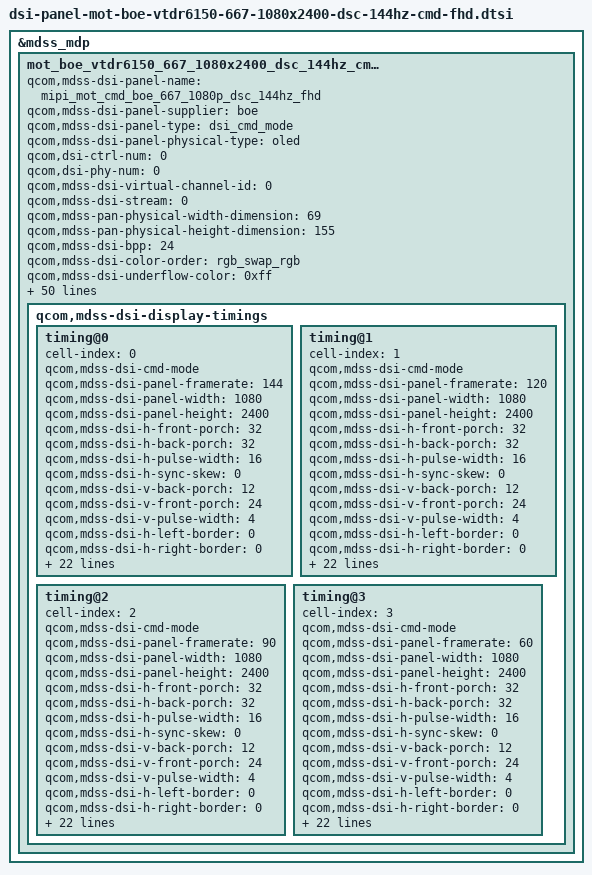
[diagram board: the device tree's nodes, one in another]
/* Copyright (c) 2019-2021, The Linux Foundation. All rights reserved.
 *
 * This program is free software; you can redistribute it and/or modify
 * it under the terms of the GNU General Public License version 2 and
 * only version 2 as published by the Free Software Foundation.
 *
 * This program is distributed in the hope that it will be useful,
 * but WITHOUT ANY WARRANTY; without even the implied warranty of
 * MERCHANTABILITY or FITNESS FOR A PARTICULAR PURPOSE.  See the
 * GNU General Public License for more details.
 */
&mdss_mdp {
	mot_boe_vtdr6150_667_1080x2400_dsc_144hz_cmd_fhd: qcom,mdss_dsi_mot_boe_vtdr6150_667_1080x2400_144hz_cmd_fhd {
		qcom,mdss-dsi-panel-name = "mipi_mot_cmd_boe_667_1080p_dsc_144hz_fhd";
		qcom,mdss-dsi-panel-supplier = "boe";
		qcom,mdss-dsi-panel-type = "dsi_cmd_mode";
		qcom,mdss-dsi-panel-physical-type = "oled";
		qcom,dsi-ctrl-num = <0>;
		qcom,dsi-phy-num = <0>;
		qcom,mdss-dsi-virtual-channel-id = <0>;
		qcom,mdss-dsi-stream = <0>;
		qcom,mdss-pan-physical-width-dimension = <69>;
		qcom,mdss-pan-physical-height-dimension = <155>;
		qcom,mdss-dsi-bpp = <24>;
		qcom,mdss-dsi-color-order = "rgb_swap_rgb";
		qcom,mdss-dsi-underflow-color = <0xff>;
		qcom,mdss-dsi-border-color = <0>;

		qcom,mdss-dsi-traffic-mode = "non_burst_sync_event";
		qcom,mdss-dsi-bllp-eof-power-mode;
		qcom,mdss-dsi-bllp-power-mode;
		qcom,mdss-dsi-lane-0-state;
		qcom,mdss-dsi-lane-1-state;
		qcom,mdss-dsi-lane-2-state;
		qcom,mdss-dsi-lane-3-state;
		qcom,mdss-dsi-dma-trigger = "trigger_sw";
		qcom,mdss-dsi-mdp-trigger = "none";
		qcom,mdss-dsi-reset-sequence = <0 0>, <1 2>, <0 2>, <1 20>;

		qcom,mdss-dsi-tx-eot-append;
		qcom,mdss-dsi-te-pin-select = <1>;
		qcom,mdss-dsi-te-dcs-command = <1>;
		qcom,mdss-dsi-te-check-enable;
		qcom,mdss-dsi-te-using-te-pin;

		qcom,mdss-dsi-dc-off-command = [
				39 01 00 00 00 00 02 5E 00];
		qcom,mdss-dsi-dc-off-command-state = "dsi_hs_mode";
		qcom,mdss-dsi-dc-on-command = [
				39 01 00 00 00 00 02 5E 01];
		qcom,mdss-dsi-dc-on-command-state = "dsi_hs_mode";

		qcom,mdss-dsi-hbm-on-command = [
				39 00 00 40 00 00 03 51 0F FF
				39 01 00 00 00 00 02 62 00];
		qcom,mdss-dsi-hbm-off-command = [
				39 00 00 40 00 00 02 62 00
				39 01 00 00 00 00 03 51 05 2A];

		qcom,mdss-dsi-hbm-fod;
		qcom,mdss-dsi-hbm-fod-on-command = [
				39 00 00 40 00 00 05 63 10 00 05 29
				39 01 00 00 00 00 02 62 03];

		qcom,mdss-dsi-panel-lhbm-wait-fps-valid;
		qcom,mdss-dsi-panel-local-hbm-wait-fps-count = <30>;
		qcom,mdss-dsi-panel-local-hbm-wait-fps-interval = <1>;
		qcom,mdss-dsi-panel-lhbm-not-allowed-fps-list = <60 90>;

		qcom,mdss-dsi-panel-local-hbm-enabled;
              	qcom,mdss-dsi-panel-local-hbm-DDIC-type = <0x6150>;
		qcom,mdss-dsi-panel-local-hbm-DC-HYBIRD-THRESHOLD-BL = <1321>; //0x0529
		qcom,mdss-dsi-panel-local-hbm-alpha-register = <0x63>;
		qcom,mdss-dsi-panel-local-hbm-alpha-size = <4096>;
		qcom,mdss-dsi-panel-bl-num = <1>;
		qcom,mdss-dsi-panel-local-hbm-alpha-table = <
				0 872 891 893 893 893 893 894 895 895 894 894 894 894 909 908
				909 910 910 911 910 909 910 910 912 913 911 929 929 929 930 931
				931 931 931 932 932 932 932 932 945 945 946 946 948 948 948 948
				949 949 948 948 966 966 965 965 966 965 964 967 967 967 967 968
				967 983 983 984 983 983 984 984 985 987 986 986 986 986 1001 1000
				1000 1001 1001 1001 1002 1002 1002 1004 1002 1003 1018 1019 1019 1018 1019 1019
				1019 1019 1019 1020 1020 1020 1023 1035 1036 1035 1035 1035 1035 1035 1035 1035
				1035 1037 1036 1036 1052 1053 1052 1052 1052 1051 1052 1053 1052 1053 1053 1054
				1053 1067 1070 1070 1071 1071 1071 1071 1070 1071 1071 1070 1071 1084 1083 1083
				1086 1086 1086 1087 1086 1087 1086 1087 1088 1088 1101 1102 1102 1102 1103 1105
				1105 1105 1105 1105 1104 1104 1105 1117 1118 1117 1117 1118 1118 1120 1120 1120
				1120 1119 1118 1134 1134 1134 1133 1134 1134 1135 1134 1137 1136 1136 1137 1136
				1150 1151 1151 1152 1150 1151 1151 1151 1152 1151 1153 1153 1153 1166 1166 1167
				1168 1167 1167 1168 1167 1168 1168 1168 1170 1183 1184 1183 1184 1185 1185 1183
				1184 1184 1185 1186 1185 1185 1201 1198 1199 1198 1199 1198 1199 1199 1199 1199
				1199 1199 1199 1213 1215 1215 1215 1215 1214 1215 1215 1215 1217 1217 1216 1217
				1229 1229 1229 1232 1233 1233 1234 1234 1233 1232 1233 1233 1245 1245 1245 1244
				1244 1246 1247 1247 1247 1248 1247 1247 1248 1260 1260 1260 1260 1261 1261 1263
				1262 1263 1264 1265 1264 1264 1276 1275 1274 1276 1276 1276 1276 1276 1280 1280
				1280 1280 1291 1291 1292 1292 1292 1293 1293 1293 1293 1294 1296 1295 1296 1308
				1308 1308 1308 1309 1309 1309 1307 1309 1308 1308 1311 1311 1322 1324 1324 1324
				1323 1323 1322 1325 1325 1324 1324 1324 1326 1339 1339 1339 1339 1349 1350 1350
				1350 1362 1361 1363 1361 1373 1373 1373 1373 1385 1385 1385 1384 1396 1396 1397
				1396 1407 1407 1407 1408 1418 1418 1417 1418 1430 1430 1431 1431 1443 1442 1444
				1445 1444 1454 1456 1456 1455 1465 1464 1466 1467 1477 1477 1476 1476 1486 1487
				1486 1486 1496 1496 1497 1498 1508 1509 1509 1511 1521 1520 1520 1520 1530 1529
				1530 1531 1540 1540 1541 1540 1542 1553 1553 1553 1552 1562 1561 1563 1564 1573
				1573 1573 1573 1583 1583 1583 1584 1593 1595 1594 1594 1604 1604 1604 1605 1612
				1613 1612 1613 1622 1624 1623 1626 1635 1635 1634 1633 1644 1646 1646 1647 1648
				1658 1657 1656 1657 1667 1667 1666 1666 1674 1676 1676 1677 1684 1686 1685 1685
				1694 1694 1694 1694 1704 1703 1704 1705 1714 1713 1712 1713 1721 1723 1723 1724
				1732 1733 1733 1736 1735 1745 1745 1745 1745 1754 1754 1754 1755 1763 1764 1764
				1762 1773 1773 1773 1773 1781 1780 1782 1780 1791 1790 1790 1788 1797 1798 1799
				1799 1808 1807 1808 1808 1816 1816 1816 1816 1819 1827 1828 1836 1836 1836 1843
				1843 1852 1853 1853 1861 1860 1869 1869 1869 1878 1879 1878 1887 1888 1896 1894
				1894 1904 1905 1912 1912 1911 1920 1920 1919 1928 1928 1936 1937 1936 1945 1944
				1950 1951 1952 1960 1958 1959 1967 1968 1975 1979 1979 1985 1985 1993 1993 1994
				2001 2002 2001 2009 2010 2018 2019 2019 2025 2027 2036 2034 2033 2042 2042 2041
				2049 2050 2058 2057 2058 2065 2063 2071 2070 2071 2078 2077 2078 2087 2087 2095
				2095 2094 2101 2101 2109 2109 2109 2114 2113 2118 2124 2126 2134 2132 2131 2139
				2139 2146 2146 2147 2154 2154 2153 2160 2162 2168 2168 2167 2175 2176 2182 2182
				2183 2191 2190 2190 2196 2199 2205 2204 2204 2211 2210 2217 2216 2217 2225 2223
				2223 2231 2231 2239 2238 2236 2243 2245 2251 2256 2255 2260 2262 2261 2268 2267
				2274 2274 2275 2281 2280 2288 2287 2288 2294 2294 2295 2301 2302 2308 2308 2309
				2313 2315 2321 2321 2322 2328 2329 2327 2334 2334 2340 2342 2341 2348 2348 2352
				2354 2355 2360 2360 2360 2368 2367 2373 2373 2377 2383 2382 2389 2389 2390 2397
				2396 2397 2402 2402 2407 2410 2408 2416 2416 2423 2422 2422 2428 2430 2429 2436
				2433 2440 2441 2441 2447 2446 2454 2453 2453 2459 2458 2458 2465 2467 2472 2472
				2473 2477 2478 2485 2485 2485 2491 2490 2495 2502 2506 2507 2512 2511 2519 2520
				2526 2534 2533 2539 2537 2544 2545 2550 2556 2553 2559 2560 2565 2566 2571 2572
				2576 2582 2580 2586 2585 2591 2592 2596 2604 2604 2609 2609 2614 2617 2621 2619
				2624 2632 2632 2637 2637 2642 2644 2649 2654 2655 2661 2662 2669 2667 2672 2674
				2679 2683 2682 2688 2689 2694 2695 2700 2705 2706 2710 2713 2716 2716 2720 2720
				2725 2732 2733 2735 2736 2741 2741 2747 2753 2754 2760 2764 2767 2767 2771 2771
				2776 2781 2781 2788 2787 2794 2793 2800 2805 2805 2810 2810 2816 2816 2821 2820
				2824 2827 2830 2834 2833 2839 2840 2845 2849 2850 2855 2854 2857 2857 2863 2863
				2869 2873 2873 2879 2880 2886 2884 2889 2893 2895 2900 2899 2902 2902 2909 2908
				2914 2917 2918 2923 2924 2928 2930 2935 2940 2940 2946 2946 2951 2949 2953 2955
				2959 2965 2963 2967 2969 2974 2974 2977 2981 2982 2987 2987 2992 2994 3001 3001
				3006 3011 3009 3014 3015 3018 3018 3025 3028 3028 3034 3035 3039 3039 3043 3044
				3050 3054 3055 3060 3058 3064 3063 3068 3071 3073 3076 3076 3081 3081 3087 3088
				3094 3097 3098 3103 3100 3107 3108 3113 3115 3115 3120 3120 3127 3126 3130 3128
				3135 3137 3139 3144 3142 3147 3148 3154 3156 3155 3160 3159 3165 3165 3167 3167
				3173 3178 3180 3180 3180 3184 3184 3188 3195 3195 3199 3199 3204 3203 3205 3216
				3218 3223 3229 3228 3231 3236 3238 3241 3245 3251 3251 3253 3257 3257 3259 3264
				3267 3268 3273 3278 3278 3284 3291 3292 3292 3296 3302 3301 3307 3308 3313 3313
				3319 3323 3324 3327 3332 3332 3336 3340 3342 3343 3346 3351 3354 3355 3359 3366
				3364 3369 3373 3373 3376 3382 3384 3385 3390 3394 3393 3397 3400 3403 3402 3407
				3409 3410 3413 3418 3420 3422 3429 3433 3433 3436 3442 3442 3447 3451 3452 3454
				3456 3462 3460 3466 3468 3468 3473 3477 3482 3481 3484 3489 3494 3495 3499 3504
				3503 3507 3511 3512 3515 3520 3523 3521 3527 3531 3533 3538 3540 3542 3542 3545
				3549 3550 3552 3557 3560 3559 3564 3568 3567 3572 3576 3580 3580 3586 3590 3589
				3594 3598 3594 3598 3600 3603 3608 3612 3612 3617 3621 3624 3626 3631 3632 3635
				3635 3639 3644 3649 3649 3654 3657 3660 3662 3664 3665 3669 3673 3679 3680 3680
				3683 3688 3692 3695 3699 3702 3707 3708 3712 3714 3719 3719 3720 3725 3731 3735
				3739 3738 3739 3743 3745 3750 3749 3751 3756 3762 3766 3769 3769 3770 3775 3777
				3783 3785 3783 3788 3791 3795 3801 3803 3803 3807 3811 3814 3820 3820 3822 3828
				3831 3835 3837 3838 3840 3842 3849 3853 3858 3856 3860 3862 3866 3870 3872 3872
				3876 3878 3882 3886 3885 3890 3893 3896 3901 3903 3902 3905 3908 3913 3917 3918
				3920 3922 3927 3930 3933 3936 3936 3938 3942 3945 3951 3951 3952 3958 3960 3964
				3968 3970 3970 3973 3978 3982 3984 3984 3990 3993 3995 3995 3999 4000 4003 4010
				4013 4015 4013 4018 4022 4024 4026 4031 4030 4033 4037 4042 4044 4046 4046 4048
				4053 4055 4060 4063 4063 4064 4065 4071 4076 4081 4096 4096 4096 4096 4096 4096
				4096 4096 4096 4096 4096 4096 4096 4096 4096 4096 4096 4096 4096 4096 4096 4096
				4096 4096 4096 4096 4096 4096 4096 4096 4096 4096 4096 4096 4096 4096 4096 4096
				4096 4096 4096 4096 4096 4096 4096 4096 4096 4096 4096 4096 4096 4096 4096 4096
				4096 4096 4096 4096 4096 4096 4096 4096 4096 4096 4096 4096 4096 4096 4096 4096
				4096 4096 4096 4096 4096 4096 4096 4096 4096 4096 4096 4096 4096 4096 4096 4096
				4096 4096 4096 4096 4096 4096 4096 4096 4096 4096 4096 4096 4096 4096 4096 4096
				4096 4096 4096 4096 4096 4096 4096 4096 4096 4096 4096 4096 4096 4096 4096 4096
				4096 4096 4096 4096 4096 4096 4096 4096 4096 4096 4096 4096 4096 4096 4096 4096
				4096 4096 4096 4096 4096 4096 4096 4096 4096 4096 4096 4096 4096 4096 4096 4096
				4096 4096 4096 4096 4096 4096 4096 4096 4096 4096 4096 4096 4096 4096 4096 4096
				4096 4096 4096 4096 4096 4096 4096 4096 4096 4096 4096 4096 4096 4096 4096 4096
				4096 4096 4096 4096 4096 4096 4096 4096 4096 4096 4096 4096 4096 4096 4096 4096
				4096 4096 4096 4096 4096 4096 4096 4096 4096 4096 4096 4096 4096 4096 4096 4096
				4096 4096 4096 4096 4096 4096 4096 4096 4096 4096 4096 4096 4096 4096 4096 4096
				4096 4096 4096 4096 4096 4096 4096 4096 4096 4096 4096 4096 4096 4096 4096 4096
				4096 4096 4096 4096 4096 4096 4096 4096 4096 4096 4096 4096 4096 4096 4096 4096
				4096 4096 4096 4096 4096 4096 4096 4096 4096 4096 4096 4096 4096 4096 4096 4096
				4096 4096 4096 4096 4096 4096 4096 4096 4096 4096 4096 4096 4096 4096 4096 4096
				4096 4096 4096 4096 4096 4096 4096 4096 4096 4096 4096 4096 4096 4096 4096 4096
				4096 4096 4096 4096 4096 4096 4096 4096 4096 4096 4096 4096 4096 4096 4096 4096
				4096 4096 4096 4096 4096 4096 4096 4096 4096 4096 4096 4096 4096 4096 4096 4096
				4096 4096 4096 4096 4096 4096 4096 4096 4096 4096 4096 4096 4096 4096 4096 4096
				4096 4096 4096 4096 4096 4096 4096 4096 4096 4096 4096 4096 4096 4096 4096 4096
				4096 4096 4096 4096 4096 4096 4096 4096 4096 4096 4096 4096 4096 4096 4096 4096
				4096 4096 4096 4096 4096 4096 4096 4096 4096 4096 4096 4096 4096 4096 4096 4096
				4096 4096 4096 4096 4096 4096 4096 4096 4096 4096 4096 4096 4096 4096 4096 4096
				4096 4096 4096 4096 4096 4096 4096 4096 4096 4096 4096 4096 4096 4096 4096 4096
				4096 4096 4096 4096 4096 4096 4096 4096 4096 4096 4096 4096 4096 4096 4096 4096
				4096 4096 4096 4096 4096 4096 4096 4096 4096 4096 4096 4096 4096 4096 4096 4096
				4096 4096 4096 4096 4096 4096 4096 4096 4096 4096 4096 4096 4096 4096 4096 4096
				4096 4096 4096 4096 4096 4096 4096 4096 4096 4096 4096 4096 4096 4096 4096 4096
				4096 4096 4096 4096 4096 4096 4096 4096 4096 4096 4096 4096 4096 4096 4096 4096
				4096 4096 4096 4096 4096 4096 4096 4096 4096 4096 4096 4096 4096 4096 4096 4096
				4096 4096 4096 4096 4096 4096 4096 4096 4096 4096 4096 4096 4096 4096 4096 4096
				4096 4096 4096 4096 4096 4096 4096 4096 4096 4096 4096 4096 4096 4096 4096 4096
				4096 4096 4096 4096 4096 4096 4096 4096 4096 4096 4096 4096 4096 4096 4096 4096
				4096 4096 4096 4096 4096 4096 4096 4096 4096 4096 4096 4096 4096 4096 4096 4096
				4096 4096 4096 4096 4096 4096 4096 4096 4096 4096 4096 4096 4096 4096 4096 4096
				4096 4096 4096 4096 4096 4096 4096 4096 4096 4096 4096 4096 4096 4096 4096 4096
				4096 4096 4096 4096 4096 4096 4096 4096 4096 4096 4096 4096 4096 4096 4096 4096
				4096 4096 4096 4096 4096 4096 4096 4096 4096 4096 4096 4096 4096 4096 4096 4096
				4096 4096 4096 4096 4096 4096 4096 4096 4096 4096 4096 4096 4096 4096 4096 4096
				4096 4096 4096 4096 4096 4096 4096 4096 4096 4096 4096 4096 4096 4096 4096 4096
				4096 4096 4096 4096 4096 4096 4096 4096 4096 4096 4096 4096 4096 4096 4096 4096
				4096 4096 4096 4096 4096 4096 4096 4096 4096 4096 4096 4096 4096 4096 4096 4096
				4096 4096 4096 4096 4096 4096 4096 4096 4096 4096 4096 4096 4096 4096 4096 4096
				4096 4096 4096 4096 4096 4096 4096 4096 4096 4096 4096 4096 4096 4096 4096 4096
				4096 4096 4096 4096 4096 4096 4096 4096 4096 4096 4096 4096 4096 4096 4096 4096
				4096 4096 4096 4096 4096 4096 4096 4096 4096 4096 4096 4096 4096 4096 4096 4096
				4096 4096 4096 4096 4096 4096 4096 4096 4096 4096 4096 4096 4096 4096 4096 4096
				4096 4096 4096 4096 4096 4096 4096 4096 4096 4096 4096 4096 4096 4096 4096 4096
				4096 4096 4096 4096 4096 4096 4096 4096 4096 4096 4096 4096 4096 4096 4096 4096
				4096 4096 4096 4096 4096 4096 4096 4096 4096 4096 4096 4096 4096 4096 4096 4096
				4096 4096 4096 4096 4096 4096 4096 4096 4096 4096 4096 4096 4096 4096 4096 4096
				4096 4096 4096 4096 4096 4096 4096 4096 4096 4096 4096 4096 4096 4096 4096 4096
				4096 4096 4096 4096 4096 4096 4096 4096 4096 4096 4096 4096 4096 4096 4096 4096
				4096 4096 4096 4096 4096 4096 4096 4096 4096 4096 4096 4096 4096 4096 4096 4096
				4096 4096 4096 4096 4096 4096 4096 4096 4096 4096 4096 4096 4096 4096 4096 4096
				4096 4096 4096 4096 4096 4096 4096 4096 4096 4096 4096 4096 4096 4096 4096 4096
				4096 4096 4096 4096 4096 4096 4096 4096 4096 4096 4096 4096 4096 4096 4096 4096
				4096 4096 4096 4096 4096 4096 4096 4096 4096 4096 4096 4096 4096 4096 4096 4096
				4096 4096 4096 4096 4096 4096 4096 4096 4096 4096 4096 4096 4096 4096 4096 4096
				4096 4096 4096 4096 4096 4096 4096 4096 4096 4096 4096 4096 4096 4096 4096 4096
				4096 4096 4096 4096 4096 4096 4096 4096 4096 4096 4096 4096 4096 4096 4096 4096
				4096 4096 4096 4096 4096 4096 4096 4096 4096 4096 4096 4096 4096 4096 4096 4096
				4096 4096 4096 4096 4096 4096 4096 4096 4096 4096 4096 4096 4096 4096 4096 4096
				4096 4096 4096 4096 4096 4096 4096 4096 4096 4096 4096 4096 4096 4096 4096 4096
				4096 4096 4096 4096 4096 4096 4096 4096 4096 4096 4096 4096 4096 4096 4096 4096
				4096 4096 4096 4096 4096 4096 4096 4096 4096 4096 4096 4096 4096 4096 4096 4096
				4096 4096 4096 4096 4096 4096 4096 4096 4096 4096 4096 4096 4096 4096 4096 4096
				4096 4096 4096 4096 4096 4096 4096 4096 4096 4096 4096 4096 4096 4096 4096 4096
				4096 4096 4096 4096 4096 4096 4096 4096 4096 4096 4096 4096 4096 4096 4096 4096
				4096 4096 4096 4096 4096 4096 4096 4096 4096 4096 4096 4096 4096 4096 4096 4096
				4096 4096 4096 4096 4096 4096 4096 4096 4096 4096 4096 4096 4096 4096 4096 4096
				4096 4096 4096 4096 4096 4096 4096 4096 4096 4096 4096 4096 4096 4096 4096 4096
				4096 4096 4096 4096 4096 4096 4096 4096 4096 4096 4096 4096 4096 4096 4096 4096
				4096 4096 4096 4096 4096 4096 4096 4096 4096 4096 4096 4096 4096 4096 4096 4096
				4096 4096 4096 4096 4096 4096 4096 4096 4096 4096 4096 4096 4096 4096 4096 4096
				4096 4096 4096 4096 4096 4096 4096 4096 4096 4096 4096 4096 4096 4096 4096 4096
				4096 4096 4096 4096 4096 4096 4096 4096 4096 4096 4096 4096 4096 4096 4096 4096
				4096 4096 4096 4096 4096 4096 4096 4096 4096 4096 4096 4096 4096 4096 4096 4096
				4096 4096 4096 4096 4096 4096 4096 4096 4096 4096 4096 4096 4096 4096 4096 4096
				4096 4096 4096 4096 4096 4096 4096 4096 4096 4096 4096 4096 4096 4096 4096 4096
				4096 4096 4096 4096 4096 4096 4096 4096 4096 4096 4096 4096 4096 4096 4096 4096
				4096 4096 4096 4096 4096 4096 4096 4096 4096 4096 4096 4096 4096 4096 4096 4096
				4096 4096 4096 4096 4096 4096 4096 4096 4096 4096 4096 4096 4096 4096 4096 4096
				4096 4096 4096 4096 4096 4096 4096 4096 4096 4096 4096 4096 4096 4096 4096 4096
				4096 4096 4096 4096 4096 4096 4096 4096 4096 4096 4096 4096 4096 4096 4096 4096
				4096 4096 4096 4096 4096 4096 4096 4096 4096 4096 4096 4096 4096 4096 4096 4096
				4096 4096 4096 4096 4096 4096 4096 4096 4096 4096 4096 4096 4096 4096 4096 4096
				4096 4096 4096 4096 4096 4096 4096 4096 4096 4096 4096 4096 4096 4096 4096 4096
				4096 4096 4096 4096 4096 4096 4096 4096 4096 4096 4096 4096 4096 4096 4096 4096
				4096 4096 4096 4096 4096 4096 4096 4096 4096 4096 4096 4096 4096 4096 4096 4096
				4096 4096 4096 4096 4096 4096 4096 4096 4096 4096 4096 4096 4096 4096 4096 4096
				4096 4096 4096 4096 4096 4096 4096 4096 4096 4096 4096 4096 4096 4096 4096 4096
				4096 4096 4096 4096 4096 4096 4096 4096 4096 4096 4096 4096 4096 4096 4096 4096
				4096 4096 4096 4096 4096 4096 4096 4096 4096 4096 4096 4096 4096 4096 4096 4096
				4096 4096 4096 4096 4096 4096 4096 4096 4096 4096 4096 4096 4096 4096 4096 4096
				4096 4096 4096 4096 4096 4096 4096 4096 4096 4096 4096 4096 4096 4096 4096 4096
				4096 4096 4096 4096 4096 4096 4096 4096 4096 4096 4096 4096 4096 4096 4096 4096
				4096 4096 4096 4096 4096 4096 4096 4096 4096 4096 4096 4096 4096 4096 4096 4096
				4096 4096 4096 4096 4096 4096 4096 4096 4096 4096 4096 4096 4096 4096 4096 4096
				4096 4096 4096 4096 4096 4096 4096 4096 4096 4096 4096 4096 4096 4096 4096 4096
				4096 4096 4096 4096 4096 4096 4096 4096 4096 4096 4096 4096 4096 4096 4096 4096
				4096 4096 4096 4096 4096 4096 4096 4096 4096 4096 4096 4096 4096 4096 4096 4096
				4096 4096 4096 4096 4096 4096 4096 4096 4096 4096 4096 4096 4096 4096 4096 4096
				4096 4096 4096 4096 4096 4096 4096 4096 4096 4096 4096 4096 4096 4096 4096 4096
				4096 4096 4096 4096 4096 4096 4096 4096 4096 4096 4096 4096 4096 4096 4096 4096
				4096 4096 4096 4096 4096 4096 4096 4096 4096 4096 4096 4096 4096 4096 4096 4096
				4096 4096 4096 4096 4096 4096 4096 4096 4096 4096 4096 4096 4096 4096 4096 4096
				4096 4096 4096 4096 4096 4096 4096 4096 4096 4096 4096 4096 4096 4096 4096 4096
				4096 4096 4096 4096 4096 4096 4096 4096 4096 4096 4096 4096 4096 4096 4096 4096
				4096 4096 4096 4096 4096 4096 4096 4096 4096 4096 4096 4096 4096 4096 4096 4096
				4096 4096 4096 4096 4096 4096 4096 4096 4096 4096 4096 4096 4096 4096 4096 4096
				4096 4096 4096 4096 4096 4096 4096 4096 4096 4096 4096 4096 4096 4096 4096 4096
				4096 4096 4096 4096 4096 4096 4096 4096 4096 4096 4096 4096 4096 4096 4096 4096
				4096 4096 4096 4096 4096 4096 4096 4096 4096 4096 4096 4096 4096 4096 4096 4096
				4096 4096 4096 4096 4096 4096 4096 4096 4096 4096 4096 4096 4096 4096 4096 4096
				4096 4096 4096 4096 4096 4096 4096 4096 4096 4096 4096 4096 4096 4096 4096 4096
				4096 4096 4096 4096 4096 4096 4096 4096 4096 4096 4096 4096 4096 4096 4096 4096
				4096 4096 4096 4096 4096 4096 4096 4096 4096 4096 4096 4096 4096 4096 4096 4096
				4096 4096 4096 4096 4096 4096 4096 4096 4096 4096 4096 4096 4096 4096 4096 4096
				4096 4096 4096 4096 4096 4096 4096 4096 4096 4096 4096 4096 4096 4096 4096 4096
				4096 4096 4096 4096 4096 4096 4096 4096 4096 4096 4096 4096 4096 4096 4096 4096
				4096 4096 4096 4096 4096 4096 4096 4096 4096 4096 4096 4096 4096 4096 4096 4096
				4096 4096 4096 4096 4096 4096 4096 4096 4096 4096 4096 4096 4096 4096 4096 4096
				4096 4096 4096 4096 4096 4096 4096 4096 4096 4096 4096 4096 4096 4096 4096 4096
				4096 4096 4096 4096 4096 4096 4096 4096 4096 4096 4096 4096 4096 4096 4096 4096
				4096 4096 4096 4096 4096 4096 4096 4096 4096 4096 4096 4096 4096 4096 4096 4096
				4096 4096 4096 4096 4096 4096 4096 4096 4096 4096 4096 4096 4096 4096 4096 4096
				4096 4096 4096 4096 4096 4096 4096 4096 4096 4096 4096 4096 4096 4096 4096 4096
				4096 4096 4096 4096 4096 4096 4096 4096 4096 4096 4096 4096 4096 4096 4096 4096
				4096 4096 4096 4096 4096 4096 4096 4096 4096 4096 4096 4096 4096 4096 4096 4096
				4096 4096 4096 4096 4096 4096 4096 4096 4096 4096 4096 4096 4096 4096 4096 4096
				4096 4096 4096 4096 4096 4096 4096 4096 4096 4096 4096 4096 4096 4096 4096 4096
				4096 4096 4096 4096 4096 4096 4096 4096 4096 4096 4096 4096 4096 4096 4096 4096
				4096 4096 4096 4096 4096 4096 4096 4096 4096 4096 4096 4096 4096 4096 4096 4096
				4096 4096 4096 4096 4096 4096 4096 4096 4096 4096 4096 4096 4096 4096 4096 4096
				4096 4096 4096 4096 4096 4096 4096 4096 4096 4096 4096 4096 4096 4096 4096 4096
				4096 4096 4096 4096 4096 4096 4096 4096 4096 4096 4096 4096 4096 4096 4096 4096
				4096 4096 4096 4096 4096 4096 4096 4096 4096 4096 4096 4096 4096 4096 4096 4096
				4096 4096 4096 4096 4096 4096 4096 4096 4096 4096 4096 4096 4096 4096 4096 4096
				4096 4096 4096 4096 4096 4096 4096 4096 4096 4096 4096 4096 4096 4096 4096 4096
				4096 4096 4096 4096 4096 4096 4096 4096 4096 4096 4096 4096 4096 4096 4096 4096
				4096 4096 4096 4096 4096 4096 4096 4096 4096 4096 4096 4096 4096 4096 4096 4096
				4096 4096 4096 4096 4096 4096 4096 4096 4096 4096 4096 4096 4096 4096 4096 4096
				4096 4096 4096 4096 4096 4096 4096 4096 4096 4096 4096 4096 4096 4096 4096 4096
				4096 4096 4096 4096 4096 4096 4096 4096 4096 4096 4096 4096 4096 4096 4096 4096
				4096 4096 4096 4096 4096 4096 4096 4096 4096 4096 4096 4096 4096 4096 4096 4096
				4096 4096 4096 4096 4096 4096 4096 4096 4096 4096 4096 4096 4096 4096 4096 4096
				4096 4096 4096 4096 4096 4096 4096 4096 4096 4096 4096 4096 4096 4096 4096 4096
				4096 4096 4096 4096 4096 4096 4096 4096 4096 4096 4096 4096 4096 4096 4096 4096
				4096 4096 4096 4096 4096 4096 4096 4096 4096 4096 4096 4096 4096 4096 4096 4096
				4096 4096 4096 4096 4096 4096 4096 4096 4096 4096 4096 4096 4096 4096 4096 4096
				4096 4096 4096 4096 4096 4096 4096 4096 4096 4096 4096 4096 4096 4096 4096 4096
				4096 4096 4096 4096 4096 4096 4096 4096 4096 4096 4096 4096 4096 4096 4096 4096
				4096 4096 4096 4096 4096 4096 4096 4096 4096 4096 4096 4096 4096 4096 4096 4096
				4096 4096 4096 4096 4096 4096 4096 4096 4096 4096 4096 4096 4096 4096 4096 4096
				4096 4096 4096 4096 4096 4096 4096 4096 4096 4096 4096 4096 4096 4096 4096 4096
				4096 4096 4096 4096 4096 4096 4096 4096 4096 4096 4096 4096 4096 4096 4096 4096
				4096 4096 4096 4096 4096 4096 4096 4096 4096 4096 4096 4096 4096 4096 4096 4096
				4096 4096 4096 4096 4096 4096 4096 4096 4096 4096 4096 4096 4096 4096 4096 4096
				4096 4096 4096 4096 4096 4096 4096 4096 4096 4096 4096 4096 4096 4096 4096 4096
				4096 4096 4096 4096 4096 4096 4096 4096 4096 4096 4096 4096 4096 4096 4096 4096
				4096 4096 4096 4096 4096 4096 4096 4096 4096 4096 4096 4096 4096 4096 4096 4096
				4096 4096 4096 4096 4096 4096 4096 4096 4096 4096 4096 4096 4096 4096 4096 4096
				4096 4096 4096 4096 4096 4096 4096 4096 4096 4096 4096 4096 4096 4096 4096 4096
				4096 4096 4096 4096 4096 4096 4096 4096 4096 4096 4096 4096 4096 4096 4096 4096
				4096 4096 4096 4096 4096 4096 4096 4096 4096 4096 4096 4096 4096 4096 4096 4096
				4096 4096 4096 4096 4096 4096 4096 4096 4096 4096 4096 4096 4096 4096 4096 4096
				4096 4096 4096 4096 4096 4096 4096 4096 4096 4096 4096 4096 4096 4096 4096 4096
				4096 4096 4096 4096 4096 4096 4096 4096 4096 4096 4096 4096 4096 4096 4096 4096
				4096 4096 4096 4096 4096 4096 4096 4096 4096 4096 4096 4096 4096 4096 4096 4096>;

		qcom,mdss-dsi-display-timings {
			timing@0 {
				cell-index = <0>;
				qcom,mdss-dsi-cmd-mode;
				qcom,mdss-dsi-panel-framerate = <144>;
				qcom,mdss-dsi-panel-width = <1080>;
				qcom,mdss-dsi-panel-height = <2400>;
				qcom,mdss-dsi-h-front-porch = <32>;
				qcom,mdss-dsi-h-back-porch = <32>;
				qcom,mdss-dsi-h-pulse-width = <16>;
				qcom,mdss-dsi-h-sync-skew = <0>;
				qcom,mdss-dsi-v-back-porch = <12>;
				qcom,mdss-dsi-v-front-porch = <24>;
				qcom,mdss-dsi-v-pulse-width = <4>;
				qcom,mdss-dsi-h-left-border = <0>;
				qcom,mdss-dsi-h-right-border = <0>;
				qcom,mdss-dsi-v-top-border = <0>;
				qcom,mdss-dsi-v-bottom-border = <0>;
				qcom,mdss-dsi-panel-jitter = <0x20 0xa>; /* 144fps +/- 2 */
				qcom,mdss-dsi-timing-switch-command = [
						39 01 00 00 10 00 02 6C 00

				];
				qcom,mdss-dsi-on-command = [
                                                39 01 00 00 00 00 02 03 01

                                                39 01 00 00 00 00 02 35 00
                                                39 01 00 00 00 00 02 53 20
                                                39 01 00 00 00 00 03 51 0D BA
                                                39 01 00 00 00 00 02 5E 00
                                                39 01 00 00 00 00 02 59 09
                                                39 01 00 00 00 00 02 6C 00
                                                39 01 00 00 00 00 02 6D 00
                                                39 01 00 00 00 00 02 6F 02
                                                39 01 00 00 00 00 59 70 11 00 00 89 30 80 09 60 04 38 00 0C 02 1C 02 1C 02 00 02 0E 00 20 01 1F 00 07 00 0C 08 BB 08 7A 18 00 10 F0 03 0C 20 00 06 0B 0B 33 0E 1C 2A 38 46 54 62 69 70 77 79 7B 7D 7E 01 02 01 00 09 40 09 BE 19 FC 19 FA 19 F8 1A 38 1A 78 1A B6 2A F6 2B 34 2B 74 3B 74 6B F4

                                                39 01 00 00 00 00 03 F0 AA 10
                                                39 01 00 00 00 00 13 D0 84 04 F0 14 70 00 39 00 1C 00 06 0B 00 36 00 06 0B 39

                                                39 01 00 00 00 00 03 F0 AA 12
                                                39 01 00 00 00 00 02 65 01
                                                39 01 00 00 00 00 02 C7 7B
                                                39 01 00 00 00 00 03 F0 AA 12
                                                39 01 00 00 00 00 02 65 10
                                                39 01 00 00 00 00 02 BF 40
                                                39 01 00 00 00 00 02 65 10
                                                39 01 00 00 00 00 02 D9 40
                                                39 01 00 00 00 00 02 65 10
                                                39 01 00 00 00 00 02 DF 40
                                                39 01 00 00 00 00 02 65 10
                                                39 01 00 00 00 00 02 EB 40
                                                39 01 00 00 00 00 03 FF 5A 80
                                                39 01 00 00 00 00 02 65 0A
                                                39 01 00 00 00 00 02 F9 A8
                                                39 01 00 00 00 00 03 FF 5A 81
                                                39 01 00 00 00 00 02 65 06
                                                39 01 00 00 00 00 02 F3 87
                                                39 01 00 00 00 00 02 65 09
                                                39 01 00 00 00 00 02 F3 00
                                                39 01 00 00 00 00 02 65 0A
                                                39 01 00 00 00 00 02 F3 10
                                                39 01 00 00 00 00 02 65 10
                                                39 01 00 00 00 00 02 F3 10

                                                39 01 00 00 55 00 01 11
                                                39 01 00 00 00 00 03 F0 AA 12
                                                39 01 00 00 00 00 02 65 10
                                                39 01 00 00 00 00 02 BF 0B
                                                39 01 00 00 00 00 02 65 10
                                                39 01 00 00 00 00 02 D9 0B
                                                39 01 00 00 00 00 02 65 10
                                                39 01 00 00 00 00 02 DF 0B
                                                39 01 00 00 00 00 02 65 10
                                                39 01 00 00 00 00 02 EB 0B

                                                39 01 00 00 00 00 03 F0 AA 00
                                                39 01 00 00 00 00 03 FF 5A 00
                                                39 01 00 00 0A 00 01 29
				];

				qcom,mdss-dsi-off-command = [
						05 01 00 00 14 00 01 28
						05 01 00 00 78 00 01 10];
				qcom,mdss-dsi-on-command-state = "dsi_lp_mode";
				qcom,mdss-dsi-off-command-state = "dsi_lp_mode";
				qcom,mdss-dsi-timing-switch-command-state =
					"dsi_lp_mode";
				qcom,mdss-dsi-h-sync-pulse = <0>;
				qcom,compression-mode = "dsc";
				qcom,mdss-dsc-version = <0x11>;
				qcom,mdss-dsc-slice-height = <12>;
				qcom,mdss-dsc-slice-width = <540>;
				qcom,mdss-dsc-slice-per-pkt = <2>;
				qcom,mdss-dsc-bit-per-component = <8>;
				qcom,mdss-dsc-bit-per-pixel = <8>;
				qcom,mdss-dsc-block-prediction-enable;


			};
			timing@1 {
				cell-index = <1>;
				qcom,mdss-dsi-cmd-mode;
				qcom,mdss-dsi-panel-framerate = <120>;
				qcom,mdss-dsi-panel-width = <1080>;
				qcom,mdss-dsi-panel-height = <2400>;
				qcom,mdss-dsi-h-front-porch = <32>;
				qcom,mdss-dsi-h-back-porch = <32>;
				qcom,mdss-dsi-h-pulse-width = <16>;
				qcom,mdss-dsi-h-sync-skew = <0>;
				qcom,mdss-dsi-v-back-porch = <12>;
				qcom,mdss-dsi-v-front-porch = <24>;
				qcom,mdss-dsi-v-pulse-width = <4>;
				qcom,mdss-dsi-h-left-border = <0>;
				qcom,mdss-dsi-h-right-border = <0>;
				qcom,mdss-dsi-v-top-border = <0>;
				qcom,mdss-dsi-v-bottom-border = <0>;
				qcom,mdss-dsi-panel-jitter = <0x20 0xa>; /* 120fps +/- 2 */
				qcom,mdss-dsi-timing-switch-command = [
						39 01 00 00 10 00 02 6C 01

				];
				qcom,mdss-dsi-on-command = [
                                               39 01 00 00 00 00 02 03 01

                                                39 01 00 00 00 00 02 35 00
                                                39 01 00 00 00 00 02 53 20
                                                39 01 00 00 00 00 03 51 0D BA
                                                39 01 00 00 00 00 02 5E 00
                                                39 01 00 00 00 00 02 59 09
                                                39 01 00 00 00 00 02 6C 01
                                                39 01 00 00 00 00 02 6D 00
                                                39 01 00 00 00 00 02 6F 02
                                                39 01 00 00 00 00 59 70 11 00 00 89 30 80 09 60 04 38 00 0C 02 1C 02 1C 02 00 02 0E 00 20 01 1F 00 07 00 0C 08 BB 08 7A 18 00 10 F0 03 0C 20 00 06 0B 0B 33 0E 1C 2A 38 46 54 62 69 70 77 79 7B 7D 7E 01 02 01 00 09 40 09 BE 19 FC 19 FA 19 F8 1A 38 1A 78 1A B6 2A F6 2B 34 2B 74 3B 74 6B F4

                                                39 01 00 00 00 00 03 F0 AA 10
                                                39 01 00 00 00 00 13 D0 84 04 F0 14 70 00 39 00 1C 00 06 0B 00 36 00 06 0B 39

                                                39 01 00 00 00 00 03 F0 AA 12
                                                39 01 00 00 00 00 02 65 01
                                                39 01 00 00 00 00 02 C7 7B
                                                39 01 00 00 00 00 03 F0 AA 12
                                                39 01 00 00 00 00 02 65 10
                                                39 01 00 00 00 00 02 BF 40
                                                39 01 00 00 00 00 02 65 10
                                                39 01 00 00 00 00 02 D9 40
                                                39 01 00 00 00 00 02 65 10
                                                39 01 00 00 00 00 02 DF 40
                                                39 01 00 00 00 00 02 65 10
                                                39 01 00 00 00 00 02 EB 40
                                                39 01 00 00 00 00 03 FF 5A 80
                                                39 01 00 00 00 00 02 65 0A
                                                39 01 00 00 00 00 02 F9 A8
                                                39 01 00 00 00 00 03 FF 5A 81
                                                39 01 00 00 00 00 02 65 06
                                                39 01 00 00 00 00 02 F3 87
                                                39 01 00 00 00 00 02 65 09
                                                39 01 00 00 00 00 02 F3 00
                                                39 01 00 00 00 00 02 65 0A
                                                39 01 00 00 00 00 02 F3 10
                                                39 01 00 00 00 00 02 65 10
                                                39 01 00 00 00 00 02 F3 10

                                                39 01 00 00 55 00 01 11
                                                39 01 00 00 00 00 03 F0 AA 12
                                                39 01 00 00 00 00 02 65 10
                                                39 01 00 00 00 00 02 BF 0B
                                                39 01 00 00 00 00 02 65 10
                                                39 01 00 00 00 00 02 D9 0B
                                                39 01 00 00 00 00 02 65 10
                                                39 01 00 00 00 00 02 DF 0B
                                                39 01 00 00 00 00 02 65 10
                                                39 01 00 00 00 00 02 EB 0B

                                                39 01 00 00 00 00 03 F0 AA 00
                                                39 01 00 00 00 00 03 FF 5A 00
                                                39 01 00 00 0A 00 01 29
				];

				qcom,mdss-dsi-off-command = [
						05 01 00 00 14 00 01 28
						05 01 00 00 78 00 01 10];
				qcom,mdss-dsi-on-command-state = "dsi_lp_mode";
				qcom,mdss-dsi-off-command-state = "dsi_lp_mode";
				qcom,mdss-dsi-timing-switch-command-state =
					"dsi_lp_mode";
				qcom,mdss-dsi-h-sync-pulse = <0>;
				qcom,compression-mode = "dsc";
				qcom,mdss-dsc-version = <0x11>;
				qcom,mdss-dsc-slice-height = <12>;
				qcom,mdss-dsc-slice-width = <540>;
				qcom,mdss-dsc-slice-per-pkt = <2>;
				qcom,mdss-dsc-bit-per-component = <8>;
				qcom,mdss-dsc-bit-per-pixel = <8>;
				qcom,mdss-dsc-block-prediction-enable;


			};
			timing@2{
				cell-index = <2>;
				qcom,mdss-dsi-cmd-mode;
				qcom,mdss-dsi-panel-framerate = <90>;
				qcom,mdss-dsi-panel-width = <1080>;
				qcom,mdss-dsi-panel-height = <2400>;
				qcom,mdss-dsi-h-front-porch = <32>;
				qcom,mdss-dsi-h-back-porch = <32>;
				qcom,mdss-dsi-h-pulse-width = <16>;
				qcom,mdss-dsi-h-sync-skew = <0>;
				qcom,mdss-dsi-v-back-porch = <12>;
				qcom,mdss-dsi-v-front-porch = <24>;
				qcom,mdss-dsi-v-pulse-width = <4>;
				qcom,mdss-dsi-h-left-border = <0>;
				qcom,mdss-dsi-h-right-border = <0>;
				qcom,mdss-dsi-v-top-border = <0>;
				qcom,mdss-dsi-v-bottom-border = <0>;
				qcom,mdss-dsi-panel-jitter = <0x20 0xa>; /* 60fps +/- 2 */
				qcom,mdss-dsi-timing-switch-command = [
						39 01 00 00 10 00 02 6C 02

				];
				qcom,mdss-dsi-on-command = [
                                               39 01 00 00 00 00 02 03 01

                                                39 01 00 00 00 00 02 35 00
                                                39 01 00 00 00 00 02 53 20
                                                39 01 00 00 00 00 03 51 0D BA
                                                39 01 00 00 00 00 02 5E 00
                                                39 01 00 00 00 00 02 59 09
                                                39 01 00 00 00 00 02 6C 02
                                                39 01 00 00 00 00 02 6D 00
                                                39 01 00 00 00 00 02 6F 02
                                                39 01 00 00 00 00 59 70 11 00 00 89 30 80 09 60 04 38 00 0C 02 1C 02 1C 02 00 02 0E 00 20 01 1F 00 07 00 0C 08 BB 08 7A 18 00 10 F0 03 0C 20 00 06 0B 0B 33 0E 1C 2A 38 46 54 62 69 70 77 79 7B 7D 7E 01 02 01 00 09 40 09 BE 19 FC 19 FA 19 F8 1A 38 1A 78 1A B6 2A F6 2B 34 2B 74 3B 74 6B F4

                                                39 01 00 00 00 00 03 F0 AA 10
                                                39 01 00 00 00 00 13 D0 84 04 F0 14 70 00 39 00 1C 00 06 0B 00 36 00 06 0B 39

                                                39 01 00 00 00 00 03 F0 AA 12
                                                39 01 00 00 00 00 02 65 01
                                                39 01 00 00 00 00 02 C7 7B
                                                39 01 00 00 00 00 03 F0 AA 12
                                                39 01 00 00 00 00 02 65 10
                                                39 01 00 00 00 00 02 BF 40
                                                39 01 00 00 00 00 02 65 10
                                                39 01 00 00 00 00 02 D9 40
                                                39 01 00 00 00 00 02 65 10
                                                39 01 00 00 00 00 02 DF 40
                                                39 01 00 00 00 00 02 65 10
                                                39 01 00 00 00 00 02 EB 40
                                                39 01 00 00 00 00 03 FF 5A 80
                                                39 01 00 00 00 00 02 65 0A
                                                39 01 00 00 00 00 02 F9 A8
                                                39 01 00 00 00 00 03 FF 5A 81
                                                39 01 00 00 00 00 02 65 06
                                                39 01 00 00 00 00 02 F3 87
                                                39 01 00 00 00 00 02 65 09
                                                39 01 00 00 00 00 02 F3 00
                                                39 01 00 00 00 00 02 65 0A
                                                39 01 00 00 00 00 02 F3 10
                                                39 01 00 00 00 00 02 65 10
                                                39 01 00 00 00 00 02 F3 10

                                                39 01 00 00 55 00 01 11
                                                39 01 00 00 00 00 03 F0 AA 12
                                                39 01 00 00 00 00 02 65 10
                                                39 01 00 00 00 00 02 BF 0B
                                                39 01 00 00 00 00 02 65 10
                                                39 01 00 00 00 00 02 D9 0B
                                                39 01 00 00 00 00 02 65 10
                                                39 01 00 00 00 00 02 DF 0B
                                                39 01 00 00 00 00 02 65 10
                                                39 01 00 00 00 00 02 EB 0B

                                                39 01 00 00 00 00 03 F0 AA 00
                                                39 01 00 00 00 00 03 FF 5A 00
                                                39 01 00 00 0A 00 01 29
				];

				qcom,mdss-dsi-off-command = [
						05 01 00 00 14 00 01 28
						05 01 00 00 78 00 01 10];
				qcom,mdss-dsi-on-command-state = "dsi_lp_mode";
				qcom,mdss-dsi-off-command-state = "dsi_hs_mode";
				qcom,mdss-dsi-timing-switch-command-state =
					"dsi_lp_mode";
				qcom,mdss-dsi-h-sync-pulse = <0>;
				qcom,compression-mode = "dsc";
				qcom,mdss-dsc-version = <0x11>;
				qcom,mdss-dsc-slice-height = <12>;
				qcom,mdss-dsc-slice-width = <540>;
				qcom,mdss-dsc-slice-per-pkt = <2>;
				qcom,mdss-dsc-bit-per-component = <8>;
				qcom,mdss-dsc-bit-per-pixel = <8>;
				qcom,mdss-dsc-block-prediction-enable;


			};

			timing@3 {
				cell-index = <3>;
				qcom,mdss-dsi-cmd-mode;
				qcom,mdss-dsi-panel-framerate = <60>;
				qcom,mdss-dsi-panel-width = <1080>;
				qcom,mdss-dsi-panel-height = <2400>;
				qcom,mdss-dsi-h-front-porch = <32>;
				qcom,mdss-dsi-h-back-porch = <32>;
				qcom,mdss-dsi-h-pulse-width = <16>;
				qcom,mdss-dsi-h-sync-skew = <0>;
				qcom,mdss-dsi-v-back-porch = <12>;
				qcom,mdss-dsi-v-front-porch = <24>;
				qcom,mdss-dsi-v-pulse-width = <4>;
				qcom,mdss-dsi-h-left-border = <0>;
				qcom,mdss-dsi-h-right-border = <0>;
				qcom,mdss-dsi-v-top-border = <0>;
				qcom,mdss-dsi-v-bottom-border = <0>;
				qcom,mdss-dsi-panel-jitter =  <0x20 0xa>;
				qcom,mdss-dsi-timing-switch-command = [
						39 01 00 00 10 00 02 6C 03

				];
				qcom,mdss-dsi-on-command = [
                                               39 01 00 00 00 00 02 03 01

                                                39 01 00 00 00 00 02 35 00
                                                39 01 00 00 00 00 02 53 20
                                                39 01 00 00 00 00 03 51 0D BA
                                                39 01 00 00 00 00 02 5E 00
                                                39 01 00 00 00 00 02 59 09
                                                39 01 00 00 00 00 02 6C 03
                                                39 01 00 00 00 00 02 6D 00
                                                39 01 00 00 00 00 02 6F 02
                                                39 01 00 00 00 00 59 70 11 00 00 89 30 80 09 60 04 38 00 0C 02 1C 02 1C 02 00 02 0E 00 20 01 1F 00 07 00 0C 08 BB 08 7A 18 00 10 F0 03 0C 20 00 06 0B 0B 33 0E 1C 2A 38 46 54 62 69 70 77 79 7B 7D 7E 01 02 01 00 09 40 09 BE 19 FC 19 FA 19 F8 1A 38 1A 78 1A B6 2A F6 2B 34 2B 74 3B 74 6B F4

                                                39 01 00 00 00 00 03 F0 AA 10
                                                39 01 00 00 00 00 13 D0 84 04 F0 14 70 00 39 00 1C 00 06 0B 00 36 00 06 0B 39

                                                39 01 00 00 00 00 03 F0 AA 12
                                                39 01 00 00 00 00 02 65 01
                                                39 01 00 00 00 00 02 C7 7B
                                                39 01 00 00 00 00 03 F0 AA 12
                                                39 01 00 00 00 00 02 65 10
                                                39 01 00 00 00 00 02 BF 40
                                                39 01 00 00 00 00 02 65 10
                                                39 01 00 00 00 00 02 D9 40
                                                39 01 00 00 00 00 02 65 10
                                                39 01 00 00 00 00 02 DF 40
                                                39 01 00 00 00 00 02 65 10
                                                39 01 00 00 00 00 02 EB 40
                                                39 01 00 00 00 00 03 FF 5A 80
                                                39 01 00 00 00 00 02 65 0A
                                                39 01 00 00 00 00 02 F9 A8
                                                39 01 00 00 00 00 03 FF 5A 81
                                                39 01 00 00 00 00 02 65 06
                                                39 01 00 00 00 00 02 F3 87
                                                39 01 00 00 00 00 02 65 09
                                                39 01 00 00 00 00 02 F3 00
                                                39 01 00 00 00 00 02 65 0A
                                                39 01 00 00 00 00 02 F3 10
                                                39 01 00 00 00 00 02 65 10
                                                39 01 00 00 00 00 02 F3 10

                                                39 01 00 00 55 00 01 11
                                                39 01 00 00 00 00 03 F0 AA 12
                                                39 01 00 00 00 00 02 65 10
                                                39 01 00 00 00 00 02 BF 0B
                                                39 01 00 00 00 00 02 65 10
                                                39 01 00 00 00 00 02 D9 0B
                                                39 01 00 00 00 00 02 65 10
                                                39 01 00 00 00 00 02 DF 0B
                                                39 01 00 00 00 00 02 65 10
                                                39 01 00 00 00 00 02 EB 0B

                                                39 01 00 00 00 00 03 F0 AA 00
                                                39 01 00 00 00 00 03 FF 5A 00
                                                39 01 00 00 0A 00 01 29
				];

				qcom,mdss-dsi-off-command = [
						05 01 00 00 14 00 01 28
						05 01 00 00 78 00 01 10];
				qcom,mdss-dsi-on-command-state = "dsi_lp_mode";
				qcom,mdss-dsi-off-command-state = "dsi_hs_mode";
				qcom,mdss-dsi-timing-switch-command-state =
					"dsi_lp_mode";
				qcom,mdss-dsi-h-sync-pulse = <0>;
				qcom,compression-mode = "dsc";
				qcom,mdss-dsc-version = <0x11>;
				qcom,mdss-dsc-slice-height = <12>;
				qcom,mdss-dsc-slice-width = <540>;
				qcom,mdss-dsc-slice-per-pkt = <2>;
				qcom,mdss-dsc-bit-per-component = <8>;
				qcom,mdss-dsc-bit-per-pixel = <8>;
				qcom,mdss-dsc-block-prediction-enable;


			};			
			
		};
	};
};
